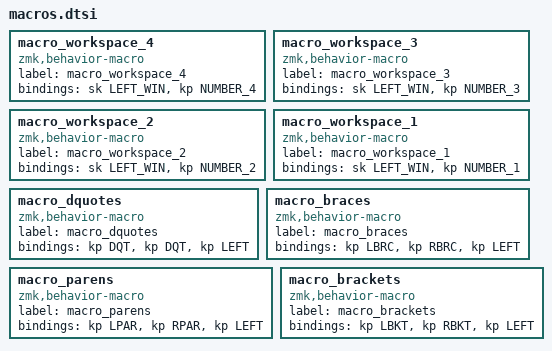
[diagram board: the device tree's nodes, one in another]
macro_workspace_4: macro_workspace_4{
compatible = "zmk,behavior-macro";
label = "macro_workspace_4";
#binding-cells = <0>;
bindings = <&sk LEFT_WIN>, <&kp NUMBER_4>;
};
macro_workspace_3: macro_workspace_3{
compatible = "zmk,behavior-macro";
label = "macro_workspace_3";
#binding-cells = <0>;
bindings = <&sk LEFT_WIN>, <&kp NUMBER_3>;
};
macro_workspace_2: macro_workspace_2{
compatible = "zmk,behavior-macro";
label = "macro_workspace_2";
#binding-cells = <0>;
bindings = <&sk LEFT_WIN>, <&kp NUMBER_2>;
};
macro_workspace_1: macro_workspace_1{
compatible = "zmk,behavior-macro";
label = "macro_workspace_1";
#binding-cells = <0>;
bindings = <&sk LEFT_WIN>, <&kp NUMBER_1>;
};
macro_dquotes: macro_dquotes{
compatible = "zmk,behavior-macro";
label = "macro_dquotes";
#binding-cells = <0>;
bindings = <&kp DQT>, <&kp DQT>, <&kp LEFT>;
};
macro_braces: macro_braces{
compatible = "zmk,behavior-macro";
label = "macro_braces";
#binding-cells = <0>;
bindings = <&kp LBRC>, <&kp RBRC>, <&kp LEFT>;
};
macro_parens: macro_parens{
compatible = "zmk,behavior-macro";
label = "macro_parens";
#binding-cells = <0>;
bindings = <&kp LPAR>, <&kp RPAR>, <&kp LEFT>;
};
macro_brackets: macro_brackets{
compatible = "zmk,behavior-macro";
label = "macro_brackets";
#binding-cells = <0>;
bindings = <&kp LBKT>, <&kp RBKT>, <&kp LEFT>;
};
